# ATmega406 register map
Vendor: Atmel; File version: 1.0
CPU: other r0p0, little endian, no MPU, no FPU, 4 interrupt priority bits
Registers are 8-bit, read-write, reset 0x0 unless marked. A register's access mark holds for its fields unless they carry their own. Offsets are from the block's base; [hi:lo] are bit positions; {n}, {i} and the like mark numbered series.

## EXINT — External Interrupts
Base 0x0000003B
0x00 PCIFR — Pin Change Interrupt Flag Register
  [1:0] PCIF — Pin Change Interrupt Flags
0x01 EIFR — External Interrupt Flag Register
  [3:0] INTF — External Interrupt Flags
0x02 EIMSK — External Interrupt Mask Register
  [3:0] INT — External Interrupt Request 1 Enable
0x2D PCICR — Pin Change Interrupt Control Register
  [1:0] PCIE — Pin Change Interrupt Enables
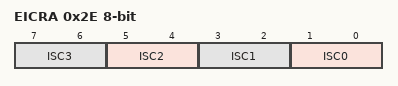
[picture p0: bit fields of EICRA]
0x2E EICRA — External Interrupt Control Register
  [all] fields
    0=Low Level of INTX; 1=Any Logical Change of INTX; 2=Falling Edge of INTX; 3=Rising Edge of INTX
  [2n+1:2n] ISC{n} (n=0..3) — External Interrupt Sense Control {n} Bits
0x30 PCMSK0 — Pin Change Enable Mask Register 0
0x31 PCMSK1 — Pin Change Enable Mask Register 1

## FET — FET Control
Base 0x000000F0
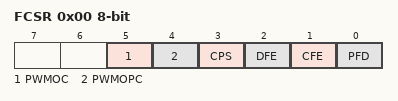
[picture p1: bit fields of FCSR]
0x00 FCSR
  [5] PWMOC — Pulse Width Modulation of OC output
  [4] PWMOPC — Pulse Width Modulation Modulation of OPC output
  [3] CPS — Current Protection Status
  [2] DFE — Discharge FET Enable
  [1] CFE — Charge FET Enable
  [0] PFD — Precharge FET disable

## FUSE — Fuses
Base 0x00000000
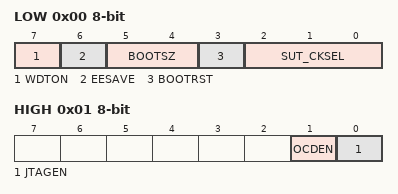
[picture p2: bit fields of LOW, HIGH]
0x00 LOW
  [7] WDTON — Watchdog timer always on
  [6] EESAVE — Preserve EEPROM through the Chip Erase cycle
  [5:4] BOOTSZ — Select boot size
    0=2048W_4800 (Boot Flash size=2048 words Boot address=$4800); 1=1024W_4C00 (Boot Flash size=1024 words Boot address=$4C00); 2=512W_4E00 (Boot Flash size=512 words Boot address=$4E00); 3=256W_4F00 (Boot Flash size=256 words Boot address=$4F00)
  [3] BOOTRST — Boot Reset vector Enabled
  [2:0] SUT_CKSEL — Clock Selection
    1=14CK_0MS (Start-up time: 14 CK + 0 ms); 3=14CK_3MS9 (Start-up time: 14 CK + 3.9 ms); 5=14CK_62MS5 (Start-up time: 14 CK + 62.5 ms)
0x01 HIGH
  [1] OCDEN — On-Chip Debug Enabled
  [0] JTAGEN — JTAG Interface Enabled

## LOCKBIT — Lockbits
Base 0x00000000
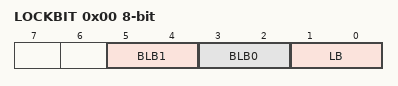
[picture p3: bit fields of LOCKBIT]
0x00 LOCKBIT
  [5:4] BLB1 — Boot Loader Protection Mode
    0=LPM_SPM_DISABLE (LPM and SPM prohibited in Boot Section); 1=LPM_DISABLE (LPM prohibited in Boot Section); 2=SPM_DISABLE (SPM prohibited in Boot Section); 3=NO_LOCK (No lock on SPM and LPM in Boot Section)
  [3:2] BLB0 — Boot Loader Protection Mode
    0=LPM_SPM_DISABLE (LPM and SPM prohibited in Application Section); 1=LPM_DISABLE (LPM prohibited in Application Section); 2=SPM_DISABLE (SPM prohibited in Application Section); 3=NO_LOCK (No lock on SPM and LPM in Application Section)
  [1:0] LB — Memory Lock
    0=PROG_VER_DISABLED (Further programming and verification disabled); 2=PROG_DISABLED (Further programming disabled); 3=NO_LOCK (No memory lock features enabled)

## PORTA — I/O Port
Base 0x00000020
0x00 PINA — Port A Input Pins
0x01 DDRA — Port A Data Direction Register
0x02 PORTA — Port A Data Register

## PORTB — I/O Port
Base 0x00000023
0x00 PINB — Port B Input Pins
0x01 DDRB — Port B Data Direction Register
0x02 PORTB — Port B Data Register

## PORTC — I/O Port
Base 0x00000028
0x00 PORTC — Port C Data Register

## PORTD — I/O Port
Base 0x00000029
0x00 PIND — Input Pins, Port D
0x01 DDRD — Data Direction Register, Port D
0x02 PORTD — Data Register, Port D

## TC0 — Timer/Counter, 8-bit
Base 0x00000035
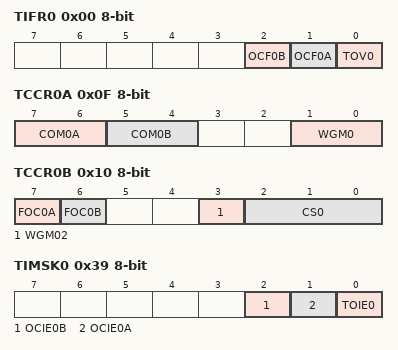
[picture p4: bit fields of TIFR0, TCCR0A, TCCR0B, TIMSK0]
0x00 TIFR0 — Timer/Counter Interrupt Flag register
  [2] OCF0B — Output Compare Flag
  [1] OCF0A — Output Compare Flag
  [0] TOV0 — Overflow Flag
0x0F TCCR0A — Timer/Counter0 Control Register
  [7:6] COM0A — Force Output Compare
  [5:4] COM0B
  [1:0] WGM0 — Clock Select0 bits
0x10 TCCR0B — Timer/Counter0 Control Register
  [7] FOC0A — Force Output Compare
  [6] FOC0B — Waveform Generation Mode
  [3] WGM02
  [2:0] CS0 — Clock Select0 bits
    0=No Clock Source (Stopped); 1=Running, No Prescaling; 2=Running, CLK/8; 3=Running, CLK/64; 4=Running, CLK/256; 5=Running, CLK/1024; 6=Running, ExtClk Tx Falling Edge; 7=Running, ExtClk Tx Rising Edge
0x11 TCNT0 — Timer Counter 0
0x12 OCR0A — Output compare Register A
0x13 OCR0B — Output compare Register B
0x39 TIMSK0 — Timer/Counter Interrupt Mask Register
  [2] OCIE0B — Output Compare Interrupt Enable
  [1] OCIE0A — Output Compare Interrupt Enable
  [0] TOIE0 — Overflow Interrupt Enable

## TC1 — Timer/Counter, 16-bit
Base 0x00000036
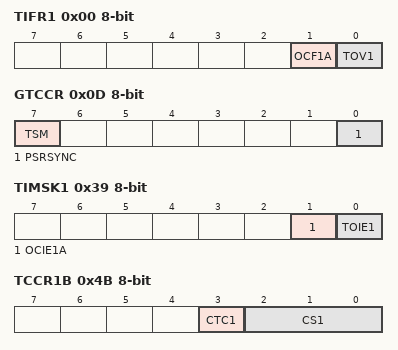
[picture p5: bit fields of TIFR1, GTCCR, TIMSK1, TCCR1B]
0x00 TIFR1 — Timer/Counter Interrupt Flag register
  [1] OCF1A — Timer/Counter1 Output Compare Flag A
  [0] TOV1 — Timer/Counter1 Overflow Flag
0x0D GTCCR — General Timer/Counter Control Register
  [7] TSM — Timer/Counter Synchronization Mode
  [0] PSRSYNC — Prescaler Reset
0x39 TIMSK1 — Timer/Counter Interrupt Mask Register
  [1] OCIE1A — Timer/Counter1 Output Compare Interrupt Enable
  [0] TOIE1 — Timer/Counter1 Overflow Interrupt Enable
0x4B TCCR1B — Timer/Counter1 Control Register B
  [3] CTC1 — Clear Timer/Counter on Compare Match
  [2:0] CS1 — Clock Select1 bits
    0=No Clock Source (Stopped); 1=Running, No Prescaling; 2=Running, CLK/8; 3=Running, CLK/32; 4=Running, CLK/64; 5=Running, CLK/128; 6=Running, CLK/256; 7=Running, CLK/1024
0x4E TCNT1 16-bit (reset mask 0xFF) — Timer Counter 1 Bytes
0x52 OCR1AL — Output Compare Register 1A Low byte
0x53 OCR1AH — Output Compare Register 1A High byte

## TWI — Two Wire Serial Interface
Base 0x000000B8
0x00 TWBR — TWI Bit Rate register
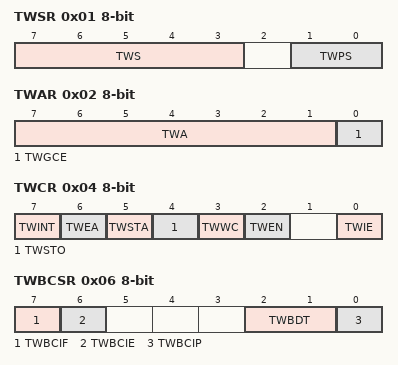
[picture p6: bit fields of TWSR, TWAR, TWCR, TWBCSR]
0x01 TWSR — TWI Status Register
  [7:3] TWS — TWI Status
  [1:0] TWPS — TWI Prescaler
    0=1; 1=4; 2=16; 3=64
0x02 TWAR — TWI (Slave) Address register
  [7:1] TWA — TWI (Slave) Address register Bits
  [0] TWGCE — TWI General Call Recognition Enable Bit
0x03 TWDR — TWI Data register
0x04 TWCR — TWI Control Register
  [7] TWINT — TWI Interrupt Flag
  [6] TWEA — TWI Enable Acknowledge Bit
  [5] TWSTA — TWI Start Condition Bit
  [4] TWSTO — TWI Stop Condition Bit
  [3] TWWC — TWI Write Collition Flag
  [2] TWEN — TWI Enable Bit
  [0] TWIE — TWI Interrupt Enable
0x05 TWAMR — TWI (Slave) Address Mask Register
  [7:1] TWAM
0x06 TWBCSR — TWI Bus Control and Status Register
  [7] TWBCIF — TWI Bus Connect/Disconnect Interrupt Flag
  [6] TWBCIE — TWI Bus Connect/Disconnect Interrupt Enable
  [2:1] TWBDT — TWI Bus Disconnect Time-out Period
    0=250ms; 1=500ms; 2=1000ms; 3=2000ms
  [0] TWBCIP — TWI Bus Connect/Disconnect Interrupt Polarity

## WAKEUP_TIMER
Base 0x00000062
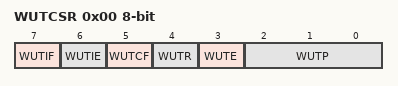
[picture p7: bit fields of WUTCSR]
0x00 WUTCSR — Wake-up Timer Control Register
  [7] WUTIF — Wake-up Timer Interrupt Flag
  [6] WUTIE — Wake-up Timer Interrupt Enable
  [5] WUTCF — Wake-up timer Calibration Flag
  [4] WUTR — Wake-up Timer Reset
  [3] WUTE — Wake-up Timer Enable
  [2:0] WUTP — Wake-up Timer Prescaler Bits
    0=4K(Slow RC) / 1K (32kHz); 1=8K(Slow RC) / 2K (32kHz); 2=16K(Slow RC) / 4K (32kHz); 3=32K(Slow RC) / 8K (32kHz); 4=64K(Slow RC) / 16K (32kHz); 5=128K(Slow RC) / 32K (32kHz); 6=256K(Slow RC) / 64K (32kHz); 7=512K(Slow RC) / 128K (32kHz)

## WDT — Watchdog Timer
Base 0x00000060
0x00 WDTCSR — Watchdog Timer Control Register
  [7] WDIF — Watchdog Timeout Interrupt Flag
  [6] WDIE — Watchdog Timeout Interrupt Enable
  [4] WDCE — Watchdog Change Enable
  [3] WDE — Watch Dog Enable
  [5:0] WDP — Watchdog Timer Prescaler Bits
    0=Oscillator Cycles 2K; 1=Oscillator Cycles 4K; 2=Oscillator Cycles 8K; 3=Oscillator Cycles 16K; 4=Oscillator Cycles 32K; 5=Oscillator Cycles 64K; 6=Oscillator Cycles 128K; 7=Oscillator Cycles 256K
